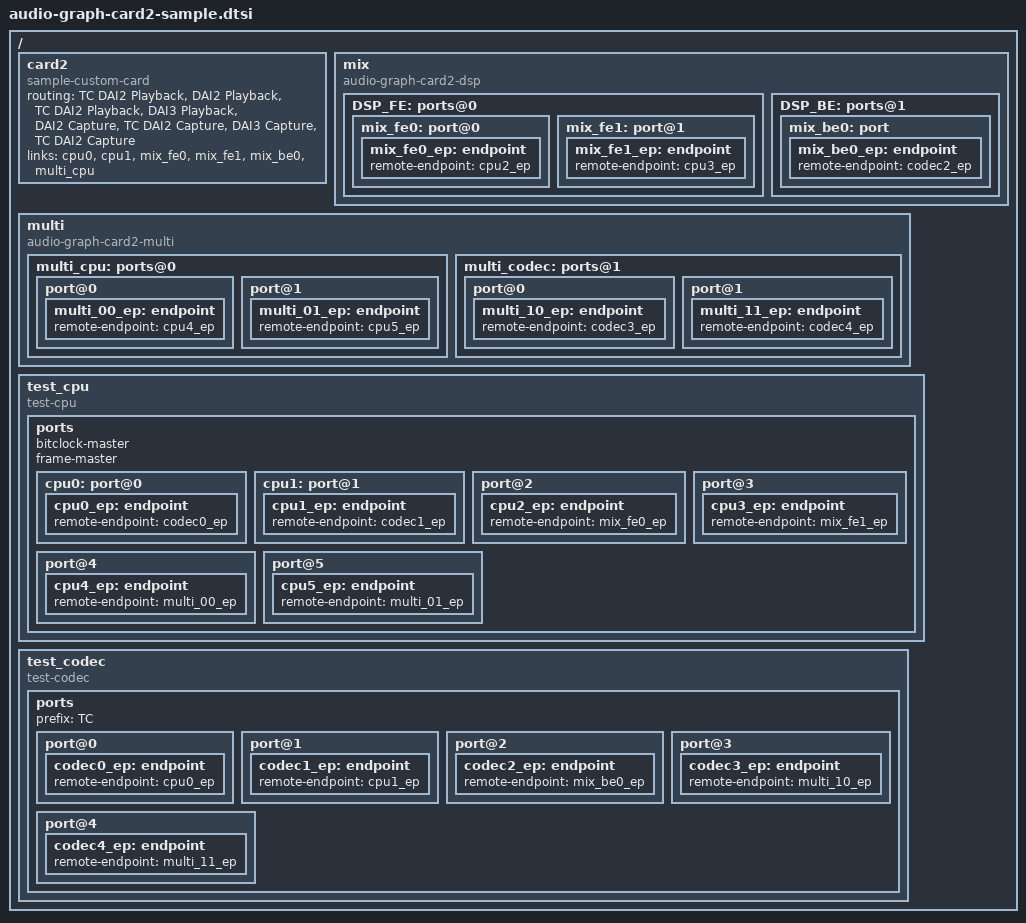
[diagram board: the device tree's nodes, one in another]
// SPDX-License-Identifier: GPL-2.0
/*
 * audio-graph-card2-sample dtsi
 *
 *
 * This sample indicates how to use audio-graph-card2 and its
 * custom driver. "sample-custom-card" is the custome driver
 * which is using audio-graph-card2.
 *
 * You can easily use this sample by adding below line on your DT file,
 * and add new CONFIG to your .config.
 *
 *	#include "../../../../../sound/soc/generic/audio-graph-card2-sample.dtsi"
 *
 *	CONFIG_SND_AUDIO_GRAPH_CARD2
 *	CONFIG_SND_SAMPLE_CUSTOM_CARD
 *	CONFIG_SND_TEST_COMPONENT
 */
/ {
	/*
	 * cpu0 <--> codec0	// Normal
	 * cpu1 <--> codec1	// Normal
	 * cpu2 <--> codec2	// DPCM
	 * cpu3 <-/		// DPCM
	 * cpu4 <==> codec3	// Multi (*1)
	 * cpu5 <==> codec4	// Multi (*1)
	 */
	card2 {
		/*
		 * You can use audio-graph-card2 directly
		 * by using
		 *
		 * compatible = "audio-graph-card2";
		 */
		compatible = "sample-custom-card";

		routing = "TC DAI2 Playback", "DAI2 Playback",
			  "TC DAI2 Playback", "DAI3 Playback",
			  "DAI2 Capture", "TC DAI2 Capture",
			  "DAI3 Capture", "TC DAI2 Capture";

		links = <&cpu0 &cpu1			/* normal: cpu side only  */
			 &mix_fe0 &mix_fe1 &mix_be0	/* dsp   : both fe/be     */
			 &multi_cpu			/* multi : cpu side only  */
		>;
	};

	mix {
		compatible = "audio-graph-card2-dsp";
		DSP_FE: ports@0 {
			mix_fe0: port@0 { mix_fe0_ep: endpoint { remote-endpoint = <&cpu2_ep>; }; };
			mix_fe1: port@1 { mix_fe1_ep: endpoint { remote-endpoint = <&cpu3_ep>; }; };
		};
		DSP_BE: ports@1 {
			mix_be0: port   { mix_be0_ep: endpoint { remote-endpoint = <&codec2_ep>; }; };
		};
	};

	multi {
		compatible = "audio-graph-card2-multi";

		/*
		 * (*1)
		 *
		 * This uses 2 CPUs x 2 Codecs as Multi connection,
		 * Because ASoC doesn't support N cpus to M codecs
		 */

		multi_cpu: ports@0 {
			port@0 { multi_00_ep: endpoint { remote-endpoint = <&cpu4_ep>; }; };
			port@1 { multi_01_ep: endpoint { remote-endpoint = <&cpu5_ep>; }; };
		};
		multi_codec: ports@1 {
			port@0 { multi_10_ep: endpoint { remote-endpoint = <&codec3_ep>; }; };
			port@1 { multi_11_ep: endpoint { remote-endpoint = <&codec4_ep>; }; };
		};
	};

	test_cpu {
		/*
		 * update compatible to indicate more detail behaviour
		 * if you want. see test-compatible for more detail.
		 *
		 *	- compatible = "test-cpu";
		 *	+ compatible = "test-cpu-nv";
		 */
		compatible = "test-cpu";
		ports {
			bitclock-master;
			frame-master;
			cpu0: port@0 { cpu0_ep: endpoint { remote-endpoint = <&codec0_ep>; }; };
			cpu1: port@1 { cpu1_ep: endpoint { remote-endpoint = <&codec1_ep>; }; };
			      port@2 { cpu2_ep: endpoint { remote-endpoint = <&mix_fe0_ep>; }; };
			      port@3 { cpu3_ep: endpoint { remote-endpoint = <&mix_fe1_ep>; }; };
			      port@4 { cpu4_ep: endpoint { remote-endpoint = <&multi_00_ep>; }; };
			      port@5 { cpu5_ep: endpoint { remote-endpoint = <&multi_01_ep>; }; };
		};
	};

	test_codec {
		/*
		 * update compatible to indicate more detail behaviour
		 * if you want. see test-compatible for more detail.
		 *
		 *	- compatible = "test-codec";
		 *	+ compatible = "test-codec-nv";
		 */
		compatible = "test-codec";
		ports {
			/*
			 * prefix can be added to *component*,
			 * see card2::routing
			 */
			prefix = "TC";

			port@0 { codec0_ep: endpoint { remote-endpoint = <&cpu0_ep>; }; };
			port@1 { codec1_ep: endpoint { remote-endpoint = <&cpu1_ep>; }; };
			port@2 { codec2_ep: endpoint { remote-endpoint = <&mix_be0_ep>; }; };
			port@3 { codec3_ep: endpoint { remote-endpoint = <&multi_10_ep>; }; };
			port@4 { codec4_ep: endpoint { remote-endpoint = <&multi_11_ep>; }; };
		};
	};
};
